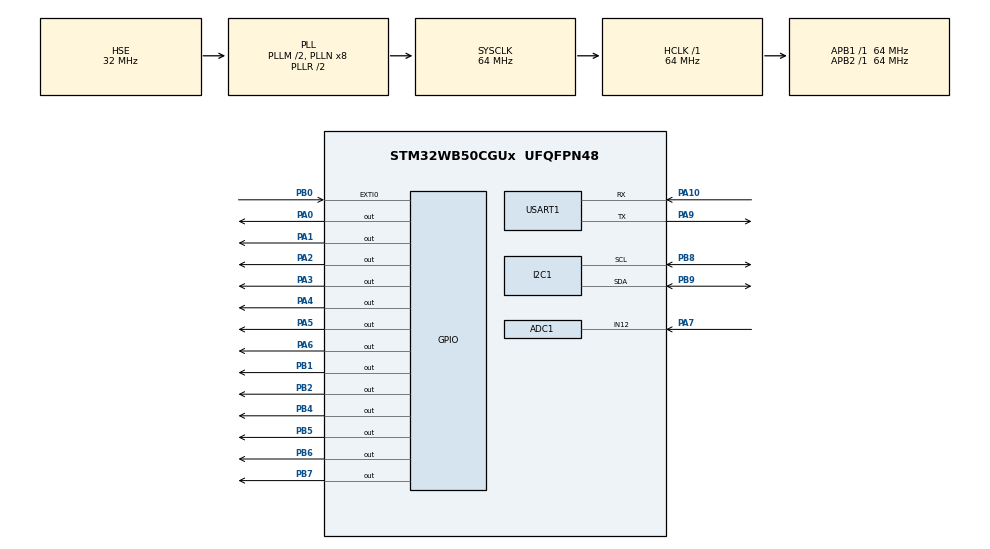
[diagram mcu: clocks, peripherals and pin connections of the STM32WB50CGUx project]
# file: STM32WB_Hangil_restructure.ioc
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ADC1.Channel-1\#ChannelRegularConversion=ADC_CHANNEL_12
ADC1.NbrOfConversionFlag=1
ADC1.OffsetNumber-1\#ChannelRegularConversion=ADC_OFFSET_NONE
ADC1.Rank-1\#ChannelRegularConversion=1
ADC1.SamplingTime-1\#ChannelRegularConversion=ADC_SAMPLETIME_92CYCLES_5
ADC1.master=1
I2C1.Timing=0x10B17DB5
Mcu.Family=STM32WB
Mcu.Name=STM32WB50CGUx
Mcu.Package=UFQFPN48
NVIC.EXTI0_IRQn=true\:0\:0\:false\:false\:true\:true\:true\:true
NVIC.PriorityGroup=NVIC_PRIORITYGROUP_4
NVIC.TIM1_TRG_COM_TIM17_IRQn=true\:0\:0\:false\:false\:true\:true\:true\:true
NVIC.TIM1_UP_TIM16_IRQn=true\:0\:0\:false\:false\:true\:true\:true\:true
OSC_IN.Mode=HSE-External-Oscillator
OSC_IN.Signal=RCC_OSC_IN
OSC_OUT.Mode=HSE-External-Oscillator
OSC_OUT.Signal=RCC_OSC_OUT
PA0.PinState=GPIO_PIN_SET
PA0.Signal=GPIO_Output
PA1.PinState=GPIO_PIN_SET
PA1.Signal=GPIO_Output
PA10.Mode=Asynchronous
PA10.Signal=USART1_RX
PA13.Mode=Serial_Wire
PA13.Signal=SYS_JTMS-SWDIO
PA14.Mode=Serial_Wire
PA14.Signal=SYS_JTCK-SWCLK
PA2.PinState=GPIO_PIN_SET
PA2.Signal=GPIO_Output
PA3.PinState=GPIO_PIN_SET
PA3.Signal=GPIO_Output
PA4.PinState=GPIO_PIN_SET
PA4.Signal=GPIO_Output
PA5.PinState=GPIO_PIN_SET
PA5.Signal=GPIO_Output
PA6.PinState=GPIO_PIN_SET
PA6.Signal=GPIO_Output
PA7.Signal=ADCx_IN12
PA9.Mode=Asynchronous
PA9.Signal=USART1_TX
PB0.GPIO_ModeDefaultEXTI=GPIO_MODE_IT_RISING_FALLING
PB0.Signal=GPXTI0
PB1.Signal=GPIO_Output
PB2.Signal=GPIO_Output
PB4.PinState=GPIO_PIN_SET
PB4.Signal=GPIO_Output
PB5.PinState=GPIO_PIN_SET
PB5.Signal=GPIO_Output
PB6.PinState=GPIO_PIN_SET
PB6.Signal=GPIO_Output
PB7.PinState=GPIO_PIN_SET
PB7.Signal=GPIO_Output
PB8.Mode=I2C
PB8.Signal=I2C1_SCL
PB9.Mode=I2C
PB9.Signal=I2C1_SDA
ProjectManager.HeapSize=0x200
ProjectManager.StackSize=0x400
ProjectManager.TargetToolchain=STM32CubeIDE
RCC.ADCFreq_Value=64000000
RCC.AHB2CLKDivider=RCC_SYSCLK_DIV2
RCC.AHBFreq_Value=64000000
RCC.APB1Freq_Value=64000000
RCC.APB1TimFreq_Value=64000000
RCC.APB2Freq_Value=64000000
RCC.APB2TimFreq_Value=64000000
RCC.APB3Freq_Value=16000000
RCC.CortexFreq_Value=64000000
RCC.HCLKFreq_Value=64000000
RCC.HSE_VALUE=32000000
RCC.HSI48_VALUE=48000000
RCC.HSI_VALUE=16000000
RCC.LSE_VALUE=32768
RCC.MSIClockRange=RCC_MSIRANGE_9
RCC.PLLM=RCC_PLLM_DIV2
RCC.PLLSourceVirtual=RCC_PLLSOURCE_HSE
RCC.SYSCLKFreq_VALUE=64000000
RCC.SYSCLKSource=RCC_SYSCLKSOURCE_PLLCLK
RCC.VCOOutputFreq_Value=128000000
SH.ADCx_IN12.0=ADC1_IN12,IN12-Single-Ended
TIM16.Period=9
TIM16.Prescaler=63
TIM17.Period=999
TIM17.Prescaler=63
TIM2.Prescaler=63
USART1.VirtualMode-Asynchronous=VM_ASYNC
VP_MEMORYMAP_VS_MEMORYMAP.Mode=CurAppReg
VP_TIM16_VS_ClockSourceINT.Mode=Enable_Timer
VP_TIM17_VS_ClockSourceINT.Mode=Enable_Timer
VP_TIM2_VS_ClockSourceINT.Mode=Internal
board=custom

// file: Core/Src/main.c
/* USER CODE BEGIN Header */
/**
  ******************************************************************************
  * @file           : main.c
  * @brief          : Main program body
  ******************************************************************************
  * @attention
  *
  * Copyright (c) 2025 STMicroelectronics.
  * All rights reserved.
  *
  * This software is licensed under terms that can be found in the LICENSE file
  * in the root directory of this software component.
  * If no LICENSE file comes with this software, it is provided AS-IS.
  *
  ******************************************************************************
  */
/* USER CODE END Header */
#include "main.h"

/* USER CODE BEGIN Includes */
#include "ap.h"
/* USER CODE END Includes */

ADC_HandleTypeDef hadc1;

I2C_HandleTypeDef hi2c1;

TIM_HandleTypeDef htim2;
TIM_HandleTypeDef htim16;
TIM_HandleTypeDef htim17;

UART_HandleTypeDef huart1;

void SystemClock_Config(void);
static void MX_GPIO_Init(void);
static void MX_I2C1_Init(void);
static void MX_USART1_UART_Init(void);
static void MX_TIM16_Init(void);
static void MX_TIM17_Init(void);
static void MX_ADC1_Init(void);
static void MX_TIM2_Init(void);

int main(void)
{

  /* MCU Configuration--------------------------------------------------------*/

  /* Reset of all peripherals, Initializes the Flash interface and the Systick. */
  HAL_Init();

  /* Configure the system clock */
  SystemClock_Config();

  /* Initialize all configured peripherals */
  MX_GPIO_Init();
  MX_I2C1_Init();
  MX_USART1_UART_Init();
  MX_TIM16_Init();
  MX_TIM17_Init();
  MX_ADC1_Init();
  MX_TIM2_Init();
  /* USER CODE BEGIN 2 */
  ap_init();
  ap_main();
  /* USER CODE END 2 */

  /* Infinite loop */
  while (1)
  {

  }
}

void SystemClock_Config(void)
{
  RCC_OscInitTypeDef RCC_OscInitStruct = {0};
  RCC_ClkInitTypeDef RCC_ClkInitStruct = {0};

  /** Initializes the RCC Oscillators according to the specified parameters
  * in the RCC_OscInitTypeDef structure.
  */
  RCC_OscInitStruct.OscillatorType = RCC_OSCILLATORTYPE_HSI|RCC_OSCILLATORTYPE_HSE;
  RCC_OscInitStruct.HSEState = RCC_HSE_ON;
  RCC_OscInitStruct.HSIState = RCC_HSI_ON;
  RCC_OscInitStruct.HSICalibrationValue = RCC_HSICALIBRATION_DEFAULT;
  RCC_OscInitStruct.PLL.PLLState = RCC_PLL_ON;
  RCC_OscInitStruct.PLL.PLLSource = RCC_PLLSOURCE_HSE;
  RCC_OscInitStruct.PLL.PLLM = RCC_PLLM_DIV2;
  RCC_OscInitStruct.PLL.PLLN = 8;
  RCC_OscInitStruct.PLL.PLLP = RCC_PLLP_DIV2;
  RCC_OscInitStruct.PLL.PLLR = RCC_PLLR_DIV2;
  RCC_OscInitStruct.PLL.PLLQ = RCC_PLLQ_DIV2;
  if (HAL_RCC_OscConfig(&RCC_OscInitStruct) != HAL_OK)
  {
    Error_Handler();
  }

  /** Configure the SYSCLKSource, HCLK, PCLK1 and PCLK2 clocks dividers
  */
  RCC_ClkInitStruct.ClockType = RCC_CLOCKTYPE_HCLK4|RCC_CLOCKTYPE_HCLK2
                              |RCC_CLOCKTYPE_HCLK|RCC_CLOCKTYPE_SYSCLK
                              |RCC_CLOCKTYPE_PCLK1|RCC_CLOCKTYPE_PCLK2;
  RCC_ClkInitStruct.SYSCLKSource = RCC_SYSCLKSOURCE_PLLCLK;
  RCC_ClkInitStruct.AHBCLKDivider = RCC_SYSCLK_DIV1;
  RCC_ClkInitStruct.APB1CLKDivider = RCC_HCLK_DIV1;
  RCC_ClkInitStruct.APB2CLKDivider = RCC_HCLK_DIV1;
  RCC_ClkInitStruct.AHBCLK2Divider = RCC_SYSCLK_DIV2;
  RCC_ClkInitStruct.AHBCLK4Divider = RCC_SYSCLK_DIV1;

  if (HAL_RCC_ClockConfig(&RCC_ClkInitStruct, FLASH_LATENCY_3) != HAL_OK)
  {
    Error_Handler();
  }
}

static void MX_ADC1_Init(void)
{

  ADC_ChannelConfTypeDef sConfig = {0};

  /** Common config
  */
  hadc1.Instance = ADC1;
  hadc1.Init.ClockPrescaler = ADC_CLOCK_ASYNC_DIV1;
  hadc1.Init.Resolution = ADC_RESOLUTION_12B;
  hadc1.Init.DataAlign = ADC_DATAALIGN_RIGHT;
  hadc1.Init.ScanConvMode = ADC_SCAN_DISABLE;
  hadc1.Init.EOCSelection = ADC_EOC_SINGLE_CONV;
  hadc1.Init.LowPowerAutoWait = DISABLE;
  hadc1.Init.ContinuousConvMode = DISABLE;
  hadc1.Init.NbrOfConversion = 1;
  hadc1.Init.DiscontinuousConvMode = DISABLE;
  hadc1.Init.ExternalTrigConv = ADC_SOFTWARE_START;
  hadc1.Init.ExternalTrigConvEdge = ADC_EXTERNALTRIGCONVEDGE_NONE;
  hadc1.Init.DMAContinuousRequests = DISABLE;
  hadc1.Init.Overrun = ADC_OVR_DATA_PRESERVED;
  hadc1.Init.OversamplingMode = DISABLE;
  if (HAL_ADC_Init(&hadc1) != HAL_OK)
  {
    Error_Handler();
  }

  /** Configure Regular Channel
  */
  sConfig.Channel = ADC_CHANNEL_12;
  sConfig.Rank = ADC_REGULAR_RANK_1;
  sConfig.SamplingTime = ADC_SAMPLETIME_92CYCLES_5;
  sConfig.SingleDiff = ADC_SINGLE_ENDED;
  sConfig.OffsetNumber = ADC_OFFSET_NONE;
  sConfig.Offset = 0;
  if (HAL_ADC_ConfigChannel(&hadc1, &sConfig) != HAL_OK)
  {
    Error_Handler();
  }

}

static void MX_I2C1_Init(void)
{

  hi2c1.Instance = I2C1;
  hi2c1.Init.Timing = 0x10B17DB5;
  hi2c1.Init.OwnAddress1 = 0;
  hi2c1.Init.AddressingMode = I2C_ADDRESSINGMODE_7BIT;
  hi2c1.Init.DualAddressMode = I2C_DUALADDRESS_DISABLE;
  hi2c1.Init.OwnAddress2 = 0;
  hi2c1.Init.OwnAddress2Masks = I2C_OA2_NOMASK;
  hi2c1.Init.GeneralCallMode = I2C_GENERALCALL_DISABLE;
  hi2c1.Init.NoStretchMode = I2C_NOSTRETCH_DISABLE;
  if (HAL_I2C_Init(&hi2c1) != HAL_OK)
  {
    Error_Handler();
  }

  /** Configure Analogue filter
  */
  if (HAL_I2CEx_ConfigAnalogFilter(&hi2c1, I2C_ANALOGFILTER_ENABLE) != HAL_OK)
  {
    Error_Handler();
  }

  /** Configure Digital filter
  */
  if (HAL_I2CEx_ConfigDigitalFilter(&hi2c1, 0) != HAL_OK)
  {
    Error_Handler();
  }

}

static void MX_TIM2_Init(void)
{

  TIM_ClockConfigTypeDef sClockSourceConfig = {0};
  TIM_MasterConfigTypeDef sMasterConfig = {0};

  htim2.Instance = TIM2;
  htim2.Init.Prescaler = 63;
  htim2.Init.CounterMode = TIM_COUNTERMODE_UP;
  htim2.Init.Period = 4294967295;
  htim2.Init.ClockDivision = TIM_CLOCKDIVISION_DIV1;
  htim2.Init.AutoReloadPreload = TIM_AUTORELOAD_PRELOAD_DISABLE;
  if (HAL_TIM_Base_Init(&htim2) != HAL_OK)
  {
    Error_Handler();
  }
  sClockSourceConfig.ClockSource = TIM_CLOCKSOURCE_INTERNAL;
  if (HAL_TIM_ConfigClockSource(&htim2, &sClockSourceConfig) != HAL_OK)
  {
    Error_Handler();
  }
  sMasterConfig.MasterOutputTrigger = TIM_TRGO_RESET;
  sMasterConfig.MasterSlaveMode = TIM_MASTERSLAVEMODE_DISABLE;
  if (HAL_TIMEx_MasterConfigSynchronization(&htim2, &sMasterConfig) != HAL_OK)
  {
    Error_Handler();
  }

}

static void MX_TIM16_Init(void)
{

  htim16.Instance = TIM16;
  htim16.Init.Prescaler = 63;
  htim16.Init.CounterMode = TIM_COUNTERMODE_UP;
  htim16.Init.Period = 29;
  htim16.Init.ClockDivision = TIM_CLOCKDIVISION_DIV1;
  htim16.Init.RepetitionCounter = 0;
  htim16.Init.AutoReloadPreload = TIM_AUTORELOAD_PRELOAD_DISABLE;
  if (HAL_TIM_Base_Init(&htim16) != HAL_OK)
  {
    Error_Handler();
  }

}

static void MX_TIM17_Init(void)
{

  htim17.Instance = TIM17;
  htim17.Init.Prescaler = 63;
  htim17.Init.CounterMode = TIM_COUNTERMODE_UP;
  htim17.Init.Period = 999;
  htim17.Init.ClockDivision = TIM_CLOCKDIVISION_DIV1;
  htim17.Init.RepetitionCounter = 0;
  htim17.Init.AutoReloadPreload = TIM_AUTORELOAD_PRELOAD_DISABLE;
  if (HAL_TIM_Base_Init(&htim17) != HAL_OK)
  {
    Error_Handler();
  }

}

static void MX_USART1_UART_Init(void)
{

  huart1.Instance = USART1;
  huart1.Init.BaudRate = 115200;
  huart1.Init.WordLength = UART_WORDLENGTH_8B;
  huart1.Init.StopBits = UART_STOPBITS_1;
  huart1.Init.Parity = UART_PARITY_NONE;
  huart1.Init.Mode = UART_MODE_TX_RX;
  huart1.Init.HwFlowCtl = UART_HWCONTROL_NONE;
  huart1.Init.OverSampling = UART_OVERSAMPLING_16;
  huart1.Init.OneBitSampling = UART_ONE_BIT_SAMPLE_DISABLE;
  huart1.Init.ClockPrescaler = UART_PRESCALER_DIV1;
  huart1.AdvancedInit.AdvFeatureInit = UART_ADVFEATURE_NO_INIT;
  if (HAL_UART_Init(&huart1) != HAL_OK)
  {
    Error_Handler();
  }
  if (HAL_UARTEx_SetTxFifoThreshold(&huart1, UART_TXFIFO_THRESHOLD_1_8) != HAL_OK)
  {
    Error_Handler();
  }
  if (HAL_UARTEx_SetRxFifoThreshold(&huart1, UART_RXFIFO_THRESHOLD_1_8) != HAL_OK)
  {
    Error_Handler();
  }
  if (HAL_UARTEx_DisableFifoMode(&huart1) != HAL_OK)
  {
    Error_Handler();
  }

}

static void MX_GPIO_Init(void)
{
  GPIO_InitTypeDef GPIO_InitStruct = {0};

  /* GPIO Ports Clock Enable */
  __HAL_RCC_GPIOB_CLK_ENABLE();
  __HAL_RCC_GPIOA_CLK_ENABLE();

  /*Configure GPIO pin Output Level */
  HAL_GPIO_WritePin(GPIOA, GPIO_PIN_0|GPIO_PIN_1|GPIO_PIN_2|GPIO_PIN_3
                          |GPIO_PIN_4|GPIO_PIN_5|GPIO_PIN_6, GPIO_PIN_SET);

  /*Configure GPIO pin Output Level */
  HAL_GPIO_WritePin(GPIOB, GPIO_PIN_2|GPIO_PIN_1, GPIO_PIN_RESET);

  /*Configure GPIO pin Output Level */
  HAL_GPIO_WritePin(GPIOB, GPIO_PIN_4|GPIO_PIN_5|GPIO_PIN_6|GPIO_PIN_7, GPIO_PIN_SET);

  /*Configure GPIO pins : PA0 PA1 PA2 PA3
                           PA4 PA5 PA6 */
  GPIO_InitStruct.Pin = GPIO_PIN_0|GPIO_PIN_1|GPIO_PIN_2|GPIO_PIN_3
                          |GPIO_PIN_4|GPIO_PIN_5|GPIO_PIN_6;
  GPIO_InitStruct.Mode = GPIO_MODE_OUTPUT_PP;
  GPIO_InitStruct.Pull = GPIO_NOPULL;
  GPIO_InitStruct.Speed = GPIO_SPEED_FREQ_LOW;
  HAL_GPIO_Init(GPIOA, &GPIO_InitStruct);

  /*Configure GPIO pins : PB2 PB1 PB4 PB5
                           PB6 PB7 */
  GPIO_InitStruct.Pin = GPIO_PIN_2|GPIO_PIN_1|GPIO_PIN_4|GPIO_PIN_5
                          |GPIO_PIN_6|GPIO_PIN_7;
  GPIO_InitStruct.Mode = GPIO_MODE_OUTPUT_PP;
  GPIO_InitStruct.Pull = GPIO_NOPULL;
  GPIO_InitStruct.Speed = GPIO_SPEED_FREQ_LOW;
  HAL_GPIO_Init(GPIOB, &GPIO_InitStruct);

  /*Configure GPIO pin : PB0 */
  GPIO_InitStruct.Pin = GPIO_PIN_0;
  GPIO_InitStruct.Mode = GPIO_MODE_IT_RISING_FALLING;
  GPIO_InitStruct.Pull = GPIO_NOPULL;
  HAL_GPIO_Init(GPIOB, &GPIO_InitStruct);

  /* EXTI interrupt init*/
  HAL_NVIC_SetPriority(EXTI0_IRQn, 0, 0);
  HAL_NVIC_EnableIRQ(EXTI0_IRQn);

}

void Error_Handler(void)
{
  __disable_irq();
  while (1)
  {
  }
}
